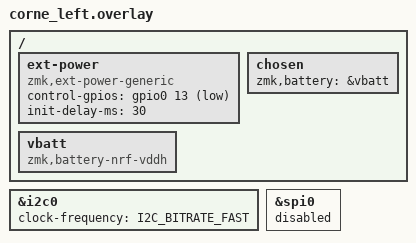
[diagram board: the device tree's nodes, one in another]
/ {
    ext-power {
        compatible = "zmk,ext-power-generic";
        control-gpios = <&gpio0 13 GPIO_ACTIVE_LOW>;
        init-delay-ms = <30>;
        status = "okay";
    };
};

/ {
    chosen {
        zmk,battery = &vbatt;
    };

    vbatt: vbatt {
        compatible = "zmk,battery-nrf-vddh";
    };
};

&i2c0 {
    status = "okay";
    clock-frequency = <I2C_BITRATE_FAST>;
};

&spi0 {
    status = "disabled";
};
